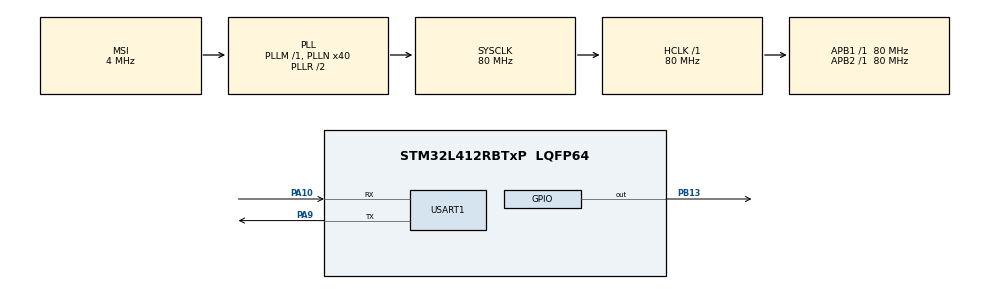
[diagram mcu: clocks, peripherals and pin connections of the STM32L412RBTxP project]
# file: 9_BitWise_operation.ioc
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Mcu.Family=STM32L4
Mcu.Name=STM32L412RBTxP
Mcu.Package=LQFP64
NVIC.PriorityGroup=NVIC_PRIORITYGROUP_4
NVIC.USART1_IRQn=true\:0\:0\:false\:false\:true\:true\:true
PA10.Mode=Asynchronous
PA10.Signal=USART1_RX
PA9.Mode=Asynchronous
PA9.Signal=USART1_TX
PB13.Signal=GPIO_Output
ProjectManager.HeapSize=0x200
ProjectManager.StackSize=0x400
ProjectManager.TargetToolchain=STM32CubeIDE
RCC.ADCFreq_Value=80000000
RCC.AHBFreq_Value=80000000
RCC.APB1Freq_Value=80000000
RCC.APB1TimFreq_Value=80000000
RCC.APB2Freq_Value=80000000
RCC.APB2TimFreq_Value=80000000
RCC.CortexFreq_Value=80000000
RCC.HCLKFreq_Value=80000000
RCC.HSE_VALUE=8000000
RCC.HSI48_VALUE=48000000
RCC.HSI_VALUE=16000000
RCC.LSE_VALUE=32768
RCC.MSI_VALUE=4000000
RCC.PLLN=40
RCC.SYSCLKFreq_VALUE=80000000
RCC.SYSCLKSource=RCC_SYSCLKSOURCE_PLLCLK
RCC.USBFreq_Value=4000000
RCC.VCOOutputFreq_Value=160000000
USART1.VirtualMode-Asynchronous=VM_ASYNC
board=custom

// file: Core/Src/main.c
/* USER CODE BEGIN Header */
/**
  ******************************************************************************
  * @file           : main.c
  * @brief          : Main program body
  ******************************************************************************
  * @attention
  *
  * <h2><center>&copy; Copyright (c) 2021 STMicroelectronics.
  * All rights reserved.</center></h2>
  *
  * This software component is licensed by ST under BSD 3-Clause license,
  * the "License"; You may not use this file except in compliance with the
  * License. You may obtain a copy of the License at:
  *                        opensource.org/licenses/BSD-3-Clause
  *
  ******************************************************************************
  */
/* USER CODE END Header */
#include "main.h"
#include "usart.h"
#include "gpio.h"

/* USER CODE BEGIN Includes */
#include <stdio.h>
#include <string.h>
/* USER CODE END Includes */

/* USER CODE BEGIN PV */

//char Q_1[] = "input address you want to know : ";
//char Q_2[] = "input value : ";
char Q_1[] = "input data : ";
uint8_t Q_wait;

uint8_t inputCheck;
uint8_t inputValue;

uint8_t reg = 0;

/* USER CODE END PV */

void SystemClock_Config(void);

/* USER CODE BEGIN 0 */
# if 0
int _write(int file, char* p, int len)
{
 HAL_UART_Transmit(&huart1, p, len, 100);
 return len;
}
#else
#ifdef __GNUC__
    #define PUTCHAR_PROTOTYPE int __io_putchar(int ch)
#else
    #define PUTCHAR_PROTOTYPE int fputc(int ch, FILE *f)
#endif

PUTCHAR_PROTOTYPE
{
  HAL_UART_Transmit(&huart1, (uint8_t *)&ch, 1, 0xFFFF);
  return ch;
}
#endif

/////////////////////////////////////

void printCur()
{
  printf("\r\nCurrent Register value : ");
  for (int idx=3; idx>=0; idx--)
  {
    if (reg&(1<<idx))
    {
      printf("1");
    }
    else
    {
      printf("0");
    }
  }
  printf("\r\n");
}

/* LED 3,4 bit */
/* 2bit check */
void CheckLed()
{
  uint8_t value = 0;
  value = (reg&(1<<3))|(reg&(1<<2));
  value = value>>2;
  if (value==2)
  {
    HAL_GPIO_WritePin(GPIOB, GPIO_PIN_13, GPIO_PIN_SET);
    printf("Led on! \r\n");
  }
  else if (value == 1)
  {
    HAL_GPIO_WritePin(GPIOB, GPIO_PIN_13, GPIO_PIN_RESET);
    printf("Led off! \r\n");
  }
}

void SetLed(uint8_t command)
{
  // init
  reg = reg&~(1<<3);
  reg = reg&~(1<<2);
  // on
  if (command&(1<<3))
  {
    reg = reg|(1<<3);
  }
  // off
  if (command&(1<<2))
  {
    reg = reg|(1<<2);
  }
  CheckLed();
}
///////////////////////

/* print 2 bit */
/* 1bit check */
////////////////////////
void CheckPrint()
{
  uint8_t value = 0;
  value = reg&(1<<1);
  value = value>>1;
  if (value==1)
  {
    printf("2bit on! \r\n");
  }
  else if (value == 0)
  {
    printf("2bit off! \r\n");
  }

}

void SetPrint(uint8_t command)
{
  // write
  if (command&(1<<1))
  {
    reg = reg|(1<<1);
  }
  // eraser
  else
  {
    reg = reg&~(1<<1);
  }
  CheckPrint();
}

void HAL_UART_RxCpltCallback(UART_HandleTypeDef *huart)
{
  HAL_UART_Receive_IT(&huart1, &inputValue, 1);
  inputCheck = 1;
}

/* USER CODE END 0 */

int main(void)
{

  /* MCU Configuration--------------------------------------------------------*/

  /* Reset of all peripherals, Initializes the Flash interface and the Systick. */
  HAL_Init();

  /* Configure the system clock */
  SystemClock_Config();

  /* Initialize all configured peripherals */
  MX_GPIO_Init();
  MX_USART1_UART_Init();
  /* USER CODE BEGIN 2 */
  HAL_UART_Receive_IT(&huart1, &inputValue, 1);

//  HAL_GPIO_WritePin(GPIOB, GPIO_PIN_13, GPIO_PIN_SET);
  printf("\r\nHello \r\n");
  Q_wait = 1;
  inputCheck = 0;
  /* USER CODE END 2 */

  /* Infinite loop */
  /* USER CODE BEGIN WHILE */

  while (1)
  {
    if (Q_wait == 1)
    {
      printCur();
      printf("%s", Q_1);
      Q_wait = 0;
    }

    if (inputCheck==1)
    {
      inputValue -= 48;
      printf("%d \r\n", inputValue);
      SetPrint(inputValue);
      SetLed(inputValue);
      inputCheck = 0;
      Q_wait = 1;
    }

    /* USER CODE END WHILE */

  }
}

void SystemClock_Config(void)
{
  RCC_OscInitTypeDef RCC_OscInitStruct = {0};
  RCC_ClkInitTypeDef RCC_ClkInitStruct = {0};
  RCC_PeriphCLKInitTypeDef PeriphClkInit = {0};

  /** Configure the main internal regulator output voltage
  */
  if (HAL_PWREx_ControlVoltageScaling(PWR_REGULATOR_VOLTAGE_SCALE1) != HAL_OK)
  {
    Error_Handler();
  }
  /** Initializes the RCC Oscillators according to the specified parameters
  * in the RCC_OscInitTypeDef structure.
  */
  RCC_OscInitStruct.OscillatorType = RCC_OSCILLATORTYPE_MSI;
  RCC_OscInitStruct.MSIState = RCC_MSI_ON;
  RCC_OscInitStruct.MSICalibrationValue = 0;
  RCC_OscInitStruct.MSIClockRange = RCC_MSIRANGE_6;
  RCC_OscInitStruct.PLL.PLLState = RCC_PLL_ON;
  RCC_OscInitStruct.PLL.PLLSource = RCC_PLLSOURCE_MSI;
  RCC_OscInitStruct.PLL.PLLM = 1;
  RCC_OscInitStruct.PLL.PLLN = 40;
  RCC_OscInitStruct.PLL.PLLQ = RCC_PLLQ_DIV2;
  RCC_OscInitStruct.PLL.PLLR = RCC_PLLR_DIV2;
  if (HAL_RCC_OscConfig(&RCC_OscInitStruct) != HAL_OK)
  {
    Error_Handler();
  }
  /** Initializes the CPU, AHB and APB buses clocks
  */
  RCC_ClkInitStruct.ClockType = RCC_CLOCKTYPE_HCLK|RCC_CLOCKTYPE_SYSCLK
                              |RCC_CLOCKTYPE_PCLK1|RCC_CLOCKTYPE_PCLK2;
  RCC_ClkInitStruct.SYSCLKSource = RCC_SYSCLKSOURCE_PLLCLK;
  RCC_ClkInitStruct.AHBCLKDivider = RCC_SYSCLK_DIV1;
  RCC_ClkInitStruct.APB1CLKDivider = RCC_HCLK_DIV1;
  RCC_ClkInitStruct.APB2CLKDivider = RCC_HCLK_DIV1;

  if (HAL_RCC_ClockConfig(&RCC_ClkInitStruct, FLASH_LATENCY_4) != HAL_OK)
  {
    Error_Handler();
  }
  PeriphClkInit.PeriphClockSelection = RCC_PERIPHCLK_USART1;
  PeriphClkInit.Usart1ClockSelection = RCC_USART1CLKSOURCE_PCLK2;
  if (HAL_RCCEx_PeriphCLKConfig(&PeriphClkInit) != HAL_OK)
  {
    Error_Handler();
  }
}

void Error_Handler(void)
{
  __disable_irq();
  while (1)
  {
  }
}

/************************ (C) COPYRIGHT STMicroelectronics *****END OF FILE****/
